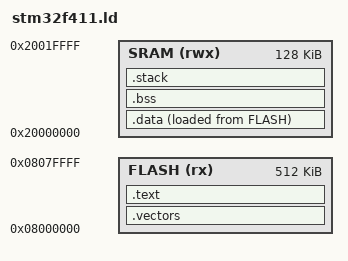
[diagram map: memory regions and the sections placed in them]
/* STM32F411CEU6: 512K FLASH, 128K SRAM */
MEMORY
{
    FLASH (rx)  : ORIGIN = 0x08000000, LENGTH = 512K
    SRAM  (rwx) : ORIGIN = 0x20000000, LENGTH = 128K
}

_stack_size = 4096;

SECTIONS
{
    .vectors :
    {
        . = ALIGN(4);
        KEEP(*(.vectors))
        . = ALIGN(4);
    } > FLASH

    .text :
    {
        . = ALIGN(4);
        *(.text*)
        *(.rodata*)
        . = ALIGN(4);
        _etext = .;
    } > FLASH

    _sidata = LOADADDR(.data);

    .data :
    {
        . = ALIGN(4);
        _sdata = .;
        *(.data*)
        . = ALIGN(4);
        _edata = .;
    } > SRAM AT> FLASH

    .bss :
    {
        . = ALIGN(4);
        _sbss = .;
        *(.bss*)
        *(COMMON)
        . = ALIGN(4);
        _ebss = .;
    } > SRAM

    .stack (NOLOAD) :
    {
        . = ALIGN(8);
        . = . + _stack_size;
        _stack_top = .;
    } > SRAM

    /DISCARD/ :
    {
        *(.ARM.exidx*)
        *(.ARM.attributes*)
    }
}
